VERSION ""

NS_ :

BS_:

BU_: VCU SENSORES BMS INVERSOR PAINEL

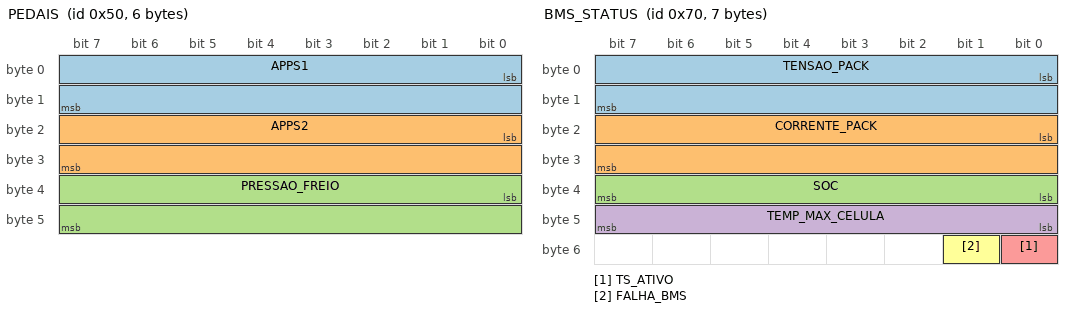
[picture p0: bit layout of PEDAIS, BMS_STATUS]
BO_ 80 PEDAIS: 6 SENSORES
 SG_ APPS1 : 0|16@1+ (0.1,0) [0|100] "%" VCU
 SG_ APPS2 : 16|16@1+ (0.1,0) [0|100] "%" VCU
 SG_ PRESSAO_FREIO : 32|16@1+ (0.1,0) [0|200] "bar" VCU

BO_ 96 VCU_CMD_INV: 3 VCU
 SG_ TORQUE_REQ : 0|16@1- (0.1,0) [-250|250] "Nm" INVERSOR
 SG_ HABILITA : 16|1@1+ (1,0) [0|1] "" INVERSOR

BO_ 112 BMS_STATUS: 7 BMS
 SG_ TENSAO_PACK : 0|16@1+ (0.1,0) [0|600] "V" VCU,PAINEL,INVERSOR
 SG_ CORRENTE_PACK : 16|16@1- (0.1,0) [-500|500] "A" VCU,PAINEL
 SG_ SOC : 32|8@1+ (0.5,0) [0|100] "%" VCU,PAINEL
 SG_ TEMP_MAX_CELULA : 40|8@1+ (1,-40) [-40|120] "C" VCU,PAINEL
 SG_ TS_ATIVO : 48|1@1+ (1,0) [0|1] "" VCU,PAINEL,INVERSOR
 SG_ FALHA_BMS : 49|1@1+ (1,0) [0|1] "" VCU,PAINEL

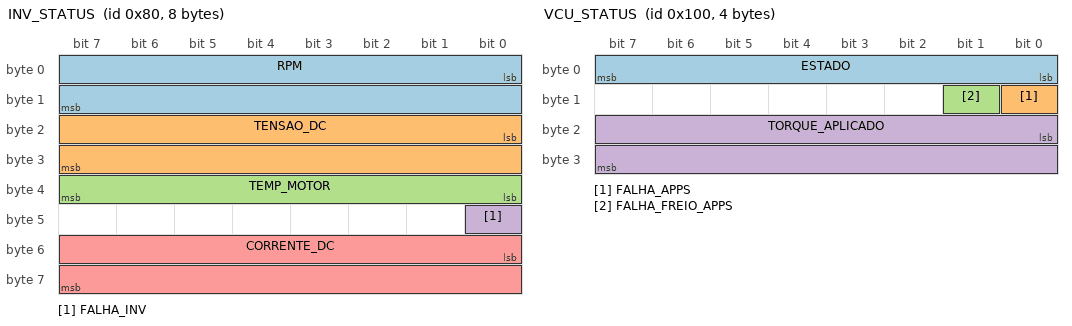
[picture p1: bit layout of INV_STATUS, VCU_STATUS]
BO_ 128 INV_STATUS: 8 INVERSOR
 SG_ RPM : 0|16@1- (1,0) [-20000|20000] "rpm" VCU,PAINEL
 SG_ TENSAO_DC : 16|16@1+ (0.1,0) [0|600] "V" VCU
 SG_ TEMP_MOTOR : 32|8@1+ (1,-40) [-40|200] "C" VCU,PAINEL
 SG_ FALHA_INV : 40|1@1+ (1,0) [0|1] "" VCU,PAINEL
 SG_ CORRENTE_DC : 48|16@1- (0.1,0) [-500|500] "A" VCU,BMS

BO_ 256 VCU_STATUS: 4 VCU
 SG_ ESTADO : 0|8@1+ (1,0) [0|4] "" PAINEL
 SG_ FALHA_APPS : 8|1@1+ (1,0) [0|1] "" PAINEL
 SG_ FALHA_FREIO_APPS : 9|1@1+ (1,0) [0|1] "" PAINEL
 SG_ TORQUE_APLICADO : 16|16@1- (0.1,0) [-250|250] "Nm" PAINEL

VAL_ 256 ESTADO 0 "DESLIGADO" 1 "PRECARGA" 2 "AGUARDA_RTD" 3 "CONDUCAO" 4 "FALHA" ;
